AUTOSAR XML (schema 00049)
package /Application/DltConfig
  dlt log channel to process mapping DltLogChannelToProcessMapping_SOA_HVAC_TO_SOA_HVAC: dlt-log-channel=SOA_HVAC, process=SOA_HVAC
package /Application/Executable
  executable SOA_HVAC: category=APPLICATION_LEVEL, logging-behavior=USES-LOGGING, reporting-behavior=REPORTS-EXECUTION-STATE, version=1.0.0
    root sw component prototype AA: application-type=SOA_HVAC
package /Application/Manifest
  service instance to port prototype mapping SOA_HVAC_AA_PPort_SOA_HVAC: port-prototype=AA.PPort_SOA_HVAC, process=SOA_HVAC, service-instance=Provider_SoaHvac
  service instance to port prototype mapping SOA_HVAC_AA_RPort_Zone5_HVAC: port-prototype=AA.RPort_Zone5_HVAC, process=SOA_HVAC, service-instance=Consumer_Zone5Hvac
package /Application/Process
  process SOA_HVAC: executable=SOA_HVAC, state-dependent-startup-config{function-group-state=[SC.On, SC.Verify], resource-group=DefaultResourceGroup, startup-config=SOA}
    process state machine SOA_HVAC: type=ProcessState
package /Application/SwComponent
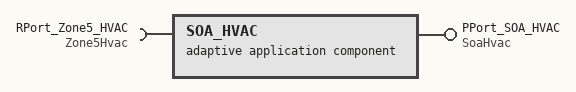
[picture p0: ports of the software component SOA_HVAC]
  adaptive application sw component type SOA_HVAC
    provide port PPort_SOA_HVAC: provided-interface=SoaHvac
    require port RPort_Zone5_HVAC: required-interface=Zone5Hvac
